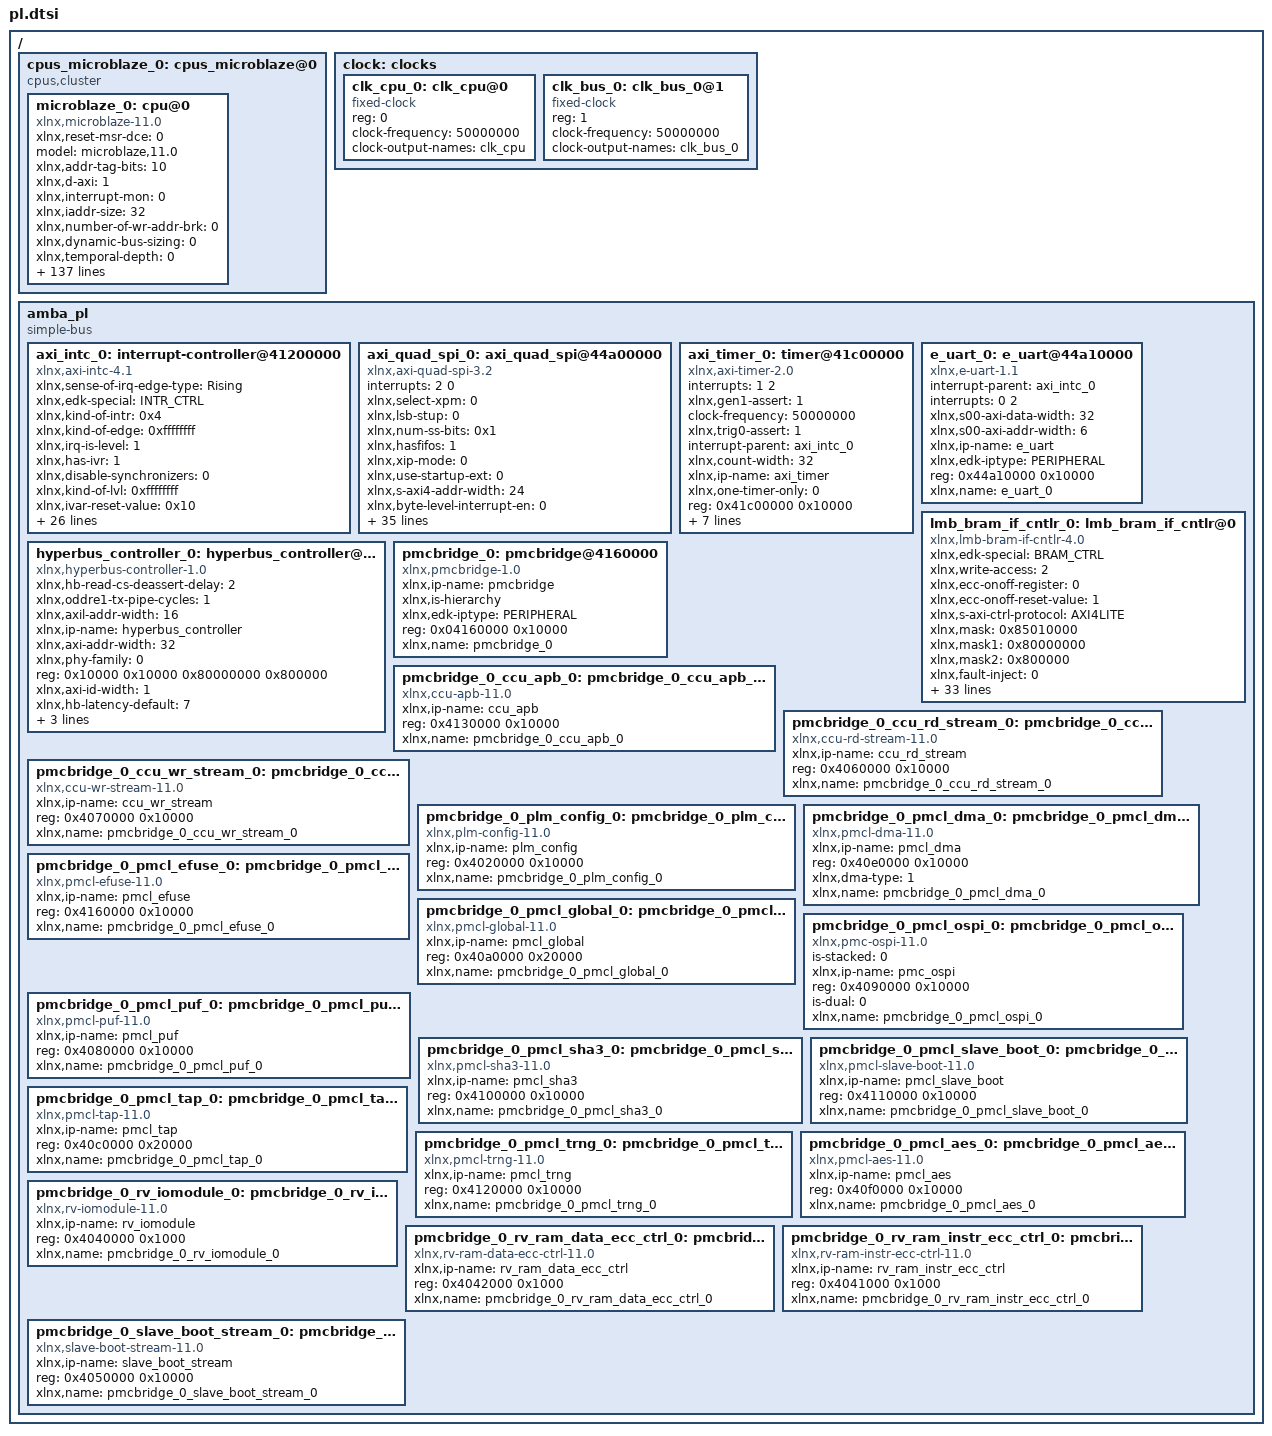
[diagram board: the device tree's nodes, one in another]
/ {
	cpus_microblaze_0: cpus_microblaze@0 {
		#cpu-mask-cells = <1>;
		compatible = "cpus,cluster";
		#address-cells = <1>;
		#size-cells = <0>;
		microblaze_0: cpu@0 {
			xlnx,reset-msr-dce = <0>;
			model = "microblaze,11.0";
			xlnx,addr-tag-bits = <10>;
			xlnx,d-axi = <1>;
			xlnx,interrupt-mon = <0>;
			xlnx,iaddr-size = <32>;
			xlnx,number-of-wr-addr-brk = <0>;
			xlnx,dynamic-bus-sizing = <0>;
			xlnx,temporal-depth = <0>;
			xlnx,use-interrupt = <1>;
			xlnx,optimization = <0>;
			xlnx,ip-axi-mon = <0>;
			xlnx,ip-name = "microblaze";
			d-cache-highaddr = <0x807fffff>;
			xlnx,dcache-force-tag-lutram = <0>;
			xlnx,pc-width = <32>;
			xlnx,interrupt-is-edge = <0>;
			reg = <0x0>;
			xlnx,async-interrupt = <1>;
			xlnx,use-mmu = <0>;
			xlnx,reset-msr-ee = <0>;
			xlnx,icache-victims = <0>;
			xlnx,use-reorder-instr = <1>;
			xlnx,d-lmb-mon = <0>;
			xlnx,d-lmb-protocol = <0>;
			xlnx,ill-opcode-exception = <1>;
			xlnx,dcache-always-used = <1>;
			xlnx,use-div = <1>;
			xlnx,dc-axi-mon = <0>;
			xlnx,debug-trace-async-reset = <0>;
			xlnx,trace = <0>;
			xlnx,part = "xcsu35p-sbvb625-2-e";
			i-cache-baseaddr = <0x80000000>;
			xlnx,use-config-reset = <0>;
			xlnx,pvr = <0>;
			xlnx,i-lmb-mon = <0>;
			xlnx,dcache-byte-size = <8192>;
			xlnx,fault-tolerant = <0>;
			xlnx,family = "spartanuplus";
			compatible = "xlnx,microblaze-11.0" , "xlnx,microblaze";
			xlnx,data-size = <32>;
			xlnx,mmu-zones = <16>;
			xlnx,debug-trace-size = <8192>;
			xlnx,mmu-privileged-instr = <0>;
			xlnx,enable-discrete-ports = <0>;
			d-cache-line-size = <32>;
			xlnx,d-lmb = <1>;
			xlnx,sco = <0>;
			xlnx,reset-msr-eip = <0>;
			xlnx,debug-interface = <0>;
			clock-frequency = <50000000>;
			xlnx,use-ext-brk = <0>;
			xlnx,daddr-size = <32>;
			xlnx,debug-enabled = <1>;
			xlnx,reset-msr-ice = <0>;
			xlnx,num-sync-ff-dbg-trace-clk = <2>;
			xlnx,i-lmb-protocol = <0>;
			xlnx,endianness = <1>;
			xlnx,fsl-exception = <0>;
			i-cache-line-size = <32>;
			xlnx,use-extended-fsl-instr = <0>;
			xlnx,reset-msr = <0x0>;
			xlnx,dp-axi-mon = <0>;
			device_type = "cpu";
			xlnx,branch-target-cache-size = <0>;
			xlnx,dcache-use-writeback = <0>;
			xlnx,div-zero-exception = <1>;
			xlnx,mmu-tlb-access = <3>;
			bus-handle = <&amba_pl>;
			xlnx,cache-byte-size = <8192>;
			xlnx,pvr-user2 = <0x0>;
			xlnx,opcode-0x0-illegal = <1>;
			xlnx,icache-line-len = <8>;
			xlnx,ecc-use-ce-exception = <0>;
			xlnx,base-vectors = <0x0>;
			xlnx,d-lmb-has-prot = <0>;
			xlnx,edk-special = "microblaze";
			xlnx,use-dcache = <1>;
			xlnx,use-barrel = <1>;
			xlnx,reset-msr-bip = <0>;
			xlnx,allow-dcache-wr = <1>;
			xlnx,debug-external-trace = <0>;
			xlnx,addr-size = <32>;
			xlnx,piaddr-size = <32>;
			i-cache-highaddr = <0x807fffff>;
			xlnx,num-sync-ff-clk-debug = <2>;
			xlnx,debug-event-counters = <5>;
			xlnx,fpu-exception = <1>;
			xlnx,allow-icache-wr = <1>;
			xlnx,g-use-exceptions = <1>;
			xlnx,i-axi = <0>;
			xlnx,g-template-list = <0>;
			xlnx,icache-streams = <0>;
			xlnx,dcache-line-len = <8>;
			xlnx,num-sync-ff-clk = <2>;
			xlnx,edk-iptype = "PROCESSOR";
			xlnx,use-stack-protection = <1>;
			xlnx,use-hw-mul = <1>;
			xlnx,num-sync-ff-dbg-clk = <1>;
			xlnx,interconnect = <2>;
			xlnx,i-lmb-has-prot = <0>;
			xlnx,debug-latency-counters = <1>;
			i-cache-size = <8192>;
			xlnx,exceptions-in-delay-slots = <1>;
			xlnx,use-fpu = <1>;
			xlnx,reset-msr-ie = <0>;
			xlnx,edge-is-positive = <1>;
			xlnx,use-pcmp-instr = <1>;
			xlnx,use-icache = <1>;
			d-cache-size = <8192>;
			xlnx,memory-ip-list = "lmb_bram_if_cntlr_0_memory" , "lmb_bram_if_cntlr_0_memory";
			xlnx,async-wakeup = <3>;
			xlnx,use-non-secure = <0>;
			xlnx,dcache-addr-tag = <10>;
			xlnx,number-of-rd-addr-brk = <0>;
			d-cache-baseaddr = <0x80000000>;
			xlnx,area-optimized = <1>;
			xlnx,avoid-primitives = <0>;
			xlnx,lockstep-slave = <0>;
			xlnx,use-ext-nm-brk = <0>;
			xlnx,instr-size = <32>;
			interrupt-handle = <&axi_intc_0>;
			xlnx,icache-always-used = <1>;
			xlnx,i-lmb = <1>;
			xlnx,mmu-dtlb-size = <4>;
			xlnx,lockstep-select = <0>;
			xlnx,lmb-data-size = <32>;
			xlnx,ic-axi-mon = <0>;
			xlnx,enable-conversion = <1>;
			xlnx,num-sync-ff-clk-irq = <1>;
			xlnx,fsl-links = <0>;
			timebase-frequency = <50000000>;
			xlnx,icache-force-tag-lutram = <0>;
			xlnx,dcache-data-width = <0>;
			xlnx,dcache-victims = <0>;
			xlnx,use-branch-target-cache = <0>;
			xlnx,debug-profile-size = <0>;
			xlnx,unaligned-exceptions = <1>;
			xlnx,lockstep-master = <0>;
			xlnx,freq = <50000000>;
			xlnx,number-of-pc-brk = <1>;
			xlnx,mmu-itlb-size = <2>;
			xlnx,imprecise-exceptions = <0>;
			xlnx,use-msr-instr = <1>;
			xlnx,icache-data-width = <0>;
			xlnx,debug-counter-width = <32>;
		};
	};
	clock: clocks {
		#address-cells = <1>;
		#size-cells = <0>;
		clk_cpu_0: clk_cpu@0 {
			compatible = "fixed-clock";
			reg = <0>;
			clock-frequency = <50000000>;
			clock-output-names = "clk_cpu";
			#clock-cells = <0>;
		};
		clk_bus_0: clk_bus_0@1 {
			compatible = "fixed-clock";
			reg = <1>;
			clock-frequency = <50000000>;
			clock-output-names = "clk_bus_0";
			#clock-cells = <0>;
		};
	};
	amba_pl: amba_pl {
		ranges;
		compatible = "simple-bus";
		#address-cells = <1>;
		#size-cells = <1>;
		axi_intc_0: interrupt-controller@41200000 {
			#interrupt-cells = <2>;
			xlnx,sense-of-irq-edge-type = "Rising";
			xlnx,edk-special = "INTR_CTRL";
			xlnx,kind-of-intr = <0x4>;
			xlnx,kind-of-edge = <0xffffffff>;
			xlnx,irq-is-level = <1>;
			xlnx,has-ivr = <1>;
			compatible = "xlnx,axi-intc-4.1" , "xlnx,xps-intc-1.00.a";
			xlnx,disable-synchronizers = <0>;
			xlnx,kind-of-lvl = <0xffffffff>;
			xlnx,ivar-reset-value = <0x10>;
			xlnx,irq-active = <0x1>;
			xlnx,en-cascade-mode = <0>;
			xlnx,ip-name = "axi_intc";
			xlnx,has-ilr = <0>;
			reg = <0x41200000 0x10000>;
			xlnx,addr-width = <0x20>;
			xlnx,s-axi-aclk-freq-mhz = <50>;
			xlnx,num-sw-intr = <0>;
			xlnx,irq-connection = <0>;
			xlnx,num-intr-inputs = <0x3>;
			xlnx,has-sie = <1>;
			xlnx,enable-async = <0>;
			xlnx,has-cie = <1>;
			xlnx,num-sync-ff = <2>;
			xlnx,edk-iptype = "PERIPHERAL";
			xlnx,mb-clk-not-connected = <1>;
			xlnx,has-ipr = <1>;
			xlnx,sense-of-irq-level-type = "Active_High";
			xlnx,cascade-master = <0>;
			xlnx,processor-clk-freq-mhz = <100>;
			status = "okay";
			xlnx,is-fast = <0x0>;
			xlnx,has-fast = <0>;
			xlnx,ivar-rst-val = <0x10>;
			interrupt-controller;
			xlnx,async-intr = <0xfffffffc>;
			xlnx,name = "axi_intc_0";
		};
		axi_quad_spi_0: axi_quad_spi@44a00000 {
			interrupts = < 2 0 >;
			xlnx,select-xpm = <0>;
			compatible = "xlnx,axi-quad-spi-3.2" , "xlnx,xps-spi-2.00.a";
			xlnx,lsb-stup = <0>;
			xlnx,num-ss-bits = <0x1>;
			xlnx,hasfifos = <1>;
			xlnx,xip-mode = <0>;
			xlnx,use-startup-ext = <0>;
			xlnx,s-axi4-addr-width = <24>;
			xlnx,byte-level-interrupt-en = <0>;
			num-cs = <0x1>;
			xlnx,xip-perf-mode = <1>;
			xlnx,sck-ratio = <2>;
			xlnx,s-axi4-id-width = <4>;
			fifo-size = <256>;
			interrupt-parent = <&axi_intc_0>;
			xlnx,multiples16 = <1>;
			xlnx,master-mode = <1>;
			xlnx,shared-startup = <0>;
			xlnx,ip-name = "axi_quad_spi";
			xlnx,qspi-board-interface = "Custom";
			reg = <0x44a00000 0x10000>;
			xlnx,dual-quad-mode = <0>;
			xlnx,new-seq-en = <1>;
			bits-per-word = <8>;
			xlnx,num-transfer-bits = <8>;
			xlnx,spi-memory = <2>;
			xlnx,s-axi4-data-width = <32>;
			xlnx,startup-block;
			xlnx,edk-iptype = "PERIPHERAL";
			xlnx,slaveonly = <0>;
			xlnx,use-startup-int = <1>;
			xlnx,use-startup = <1>;
			xlnx,type-of-axi4-interface = <0>;
			xlnx,async-clk = <0>;
			xlnx,spi-mode = <2>;
			xlnx,sck-ratio1 = <1>;
			status = "okay";
			xlnx,fifo-depth = <256>;
			xlnx,uc-family = <1>;
			xlnx,spi-mem-addr-bits = <24>;
			xlnx,axi-interface = <0>;
			interrupt-names = "ip2intc_irpt";
			xlnx,Axi4-address = <0>;
			xlnx,fifo-included = <1>;
			xlnx,sub-family = "spartanuplus";
			xlnx,name = "axi_quad_spi_0";
		};
		axi_timer_0: timer@41c00000 {
			interrupts = < 1 2 >;
			compatible = "xlnx,axi-timer-2.0" , "xlnx,xps-timer-1.00.a";
			xlnx,gen1-assert = <1>;
			clock-frequency = <50000000>;
			xlnx,trig0-assert = <1>;
			interrupt-parent = <&axi_intc_0>;
			xlnx,count-width = <32>;
			xlnx,ip-name = "axi_timer";
			xlnx,one-timer-only = <0>;
			reg = <0x41c00000 0x10000>;
			clocks = <&clk_bus_0>;
			xlnx,gen0-assert = <1>;
			xlnx,mode-64bit = <0>;
			xlnx,edk-iptype = "PERIPHERAL";
			status = "okay";
			xlnx,trig1-assert = <1>;
			xlnx,enable-timer2 = <1>;
			interrupt-names = "interrupt";
			xlnx,name = "axi_timer_0";
		};
		e_uart_0: e_uart@44a10000 {
			interrupt-parent = <&axi_intc_0>;
			interrupts = < 0 2 >;
			xlnx,s00-axi-data-width = <32>;
			compatible = "xlnx,e-uart-1.1";
			status = "okay";
			xlnx,s00-axi-addr-width = <6>;
			xlnx,ip-name = "e_uart";
			interrupt-names = "intr";
			xlnx,edk-iptype = "PERIPHERAL";
			reg = <0x44a10000 0x10000>;
			xlnx,name = "e_uart_0";
		};
		hyperbus_controller_0: hyperbus_controller@10000 {
			compatible = "xlnx,hyperbus-controller-1.0";
			xlnx,hb-read-cs-deassert-delay = <2>;
			xlnx,oddre1-tx-pipe-cycles = <1>;
			xlnx,axil-addr-width = <16>;
			xlnx,ip-name = "hyperbus_controller";
			xlnx,axi-addr-width = <32>;
			xlnx,phy-family = <0>;
			reg = <0x10000 0x10000 0x80000000 0x800000>;
			xlnx,axi-id-width = <1>;
			xlnx,hb-latency-default = <7>;
			xlnx,edk-iptype = "PERIPHERAL";
			status = "okay";
			xlnx,axi-data-width = <32>;
			xlnx,name = "hyperbus_controller_0";
		};
		lmb_bram_if_cntlr_0: lmb_bram_if_cntlr@0 {
			xlnx,edk-special = "BRAM_CTRL";
			xlnx,write-access = <2>;
			compatible = "xlnx,lmb-bram-if-cntlr-4.0" , "xlnx,axi-bram-ctrl";
			xlnx,ecc-onoff-register = <0>;
			xlnx,ecc-onoff-reset-value = <1>;
			xlnx,s-axi-ctrl-protocol = "AXI4LITE";
			xlnx,mask = <0x85010000>;
			xlnx,mask1 = <0x80000000>;
			xlnx,mask2 = <0x800000>;
			xlnx,fault-inject = <0>;
			xlnx,mask3 = <0x800000>;
			xlnx,ip-name = "lmb_bram_if_cntlr";
			xlnx,arbitration = <0>;
			xlnx,num-lmb = <2>;
			xlnx,mask4 = <0x800000>;
			reg = <0x0000 0x8000>;
			xlnx,s-axi-ctrl-addr-width = <32>;
			xlnx,mask5 = <0x800000>;
			xlnx,ecc-status-registers = <0>;
			xlnx,prot-cfg = <0xff>;
			xlnx,mask6 = <0x800000>;
			xlnx,lmb-protocol = <0>;
			xlnx,ce-counter-width = <0>;
			xlnx,prot-cfg1 = <0xff>;
			xlnx,mask7 = <0x800000>;
			xlnx,ecc = <0>;
			xlnx,edk-iptype = "PERIPHERAL";
			xlnx,prot-cfg2 = <0xff>;
			xlnx,lmb-dwidth = <32>;
			xlnx,interconnect = <0>;
			xlnx,ce-failing-registers = <0>;
			xlnx,prot-cfg3 = <0xff>;
			xlnx,ue-failing-registers = <0>;
			xlnx,prot-cfg4 = <0xff>;
			xlnx,lmb-has-prot = <0>;
			status = "okay";
			xlnx,data-width = <32>;
			xlnx,prot-cfg5 = <0xff>;
			xlnx,s-axi-ctrl-data-width = <32>;
			xlnx,prot-cfg6 = <0xff>;
			xlnx,bram-awidth = <32>;
			xlnx,prot-cfg7 = <0xff>;
			xlnx,lmb-awidth = <32>;
			xlnx,name = "lmb_bram_if_cntlr_0";
		};
		pmcbridge_0: pmcbridge@4160000 {
			compatible = "xlnx,pmcbridge-1.0";
			status = "okay";
			xlnx,ip-name = "pmcbridge";
			xlnx,is-hierarchy;
			xlnx,edk-iptype = "PERIPHERAL";
			reg = <0x04160000 0x10000>;
			xlnx,name = "pmcbridge_0";
		};
		pmcbridge_0_ccu_apb_0: pmcbridge_0_ccu_apb_0@4130000 {
			compatible = "xlnx,ccu-apb-11.0";
			status = "okay";
			xlnx,ip-name = "ccu_apb";
			reg = <0x4130000 0x10000>;
			xlnx,name = "pmcbridge_0_ccu_apb_0";
		};
		pmcbridge_0_ccu_rd_stream_0: pmcbridge_0_ccu_rd_stream_0@4060000 {
			compatible = "xlnx,ccu-rd-stream-11.0";
			status = "okay";
			xlnx,ip-name = "ccu_rd_stream";
			reg = <0x4060000 0x10000>;
			xlnx,name = "pmcbridge_0_ccu_rd_stream_0";
		};
		pmcbridge_0_ccu_wr_stream_0: pmcbridge_0_ccu_wr_stream_0@4070000 {
			compatible = "xlnx,ccu-wr-stream-11.0";
			status = "okay";
			xlnx,ip-name = "ccu_wr_stream";
			reg = <0x4070000 0x10000>;
			xlnx,name = "pmcbridge_0_ccu_wr_stream_0";
		};
		pmcbridge_0_plm_config_0: pmcbridge_0_plm_config_0@4020000 {
			compatible = "xlnx,plm-config-11.0";
			status = "okay";
			xlnx,ip-name = "plm_config";
			reg = <0x4020000 0x10000>;
			xlnx,name = "pmcbridge_0_plm_config_0";
		};
		pmcbridge_0_pmcl_dma_0: pmcbridge_0_pmcl_dma_0@40e0000 {
			compatible = "xlnx,pmcl-dma-11.0" , "xlnx,pmc-dma";
			status = "okay";
			xlnx,ip-name = "pmcl_dma";
			reg = <0x40e0000 0x10000>;
			xlnx,dma-type = <1>;
			xlnx,name = "pmcbridge_0_pmcl_dma_0";
		};
		pmcbridge_0_pmcl_efuse_0: pmcbridge_0_pmcl_efuse_0@4160000 {
			compatible = "xlnx,pmcl-efuse-11.0";
			status = "okay";
			xlnx,ip-name = "pmcl_efuse";
			reg = <0x4160000 0x10000>;
			xlnx,name = "pmcbridge_0_pmcl_efuse_0";
		};
		pmcbridge_0_pmcl_global_0: pmcbridge_0_pmcl_global_0@40a0000 {
			compatible = "xlnx,pmcl-global-11.0";
			status = "okay";
			xlnx,ip-name = "pmcl_global";
			reg = <0x40a0000 0x20000>;
			xlnx,name = "pmcbridge_0_pmcl_global_0";
		};
		pmcbridge_0_pmcl_ospi_0: pmcbridge_0_pmcl_ospi_0@4090000 {
			is-stacked = <0>;
			compatible = "xlnx,pmc-ospi-11.0" , "xlnx,pmc-ospi";
			status = "okay";
			xlnx,ip-name = "pmc_ospi";
			reg = <0x4090000 0x10000>;
			is-dual = <0>;
			xlnx,name = "pmcbridge_0_pmcl_ospi_0";
		};
		pmcbridge_0_pmcl_puf_0: pmcbridge_0_pmcl_puf_0@4080000 {
			compatible = "xlnx,pmcl-puf-11.0";
			status = "okay";
			xlnx,ip-name = "pmcl_puf";
			reg = <0x4080000 0x10000>;
			xlnx,name = "pmcbridge_0_pmcl_puf_0";
		};
		pmcbridge_0_pmcl_sha3_0: pmcbridge_0_pmcl_sha3_0@4100000 {
			compatible = "xlnx,pmcl-sha3-11.0";
			status = "okay";
			xlnx,ip-name = "pmcl_sha3";
			reg = <0x4100000 0x10000>;
			xlnx,name = "pmcbridge_0_pmcl_sha3_0";
		};
		pmcbridge_0_pmcl_slave_boot_0: pmcbridge_0_pmcl_slave_boot_0@4110000 {
			compatible = "xlnx,pmcl-slave-boot-11.0";
			status = "okay";
			xlnx,ip-name = "pmcl_slave_boot";
			reg = <0x4110000 0x10000>;
			xlnx,name = "pmcbridge_0_pmcl_slave_boot_0";
		};
		pmcbridge_0_pmcl_tap_0: pmcbridge_0_pmcl_tap_0@40c0000 {
			compatible = "xlnx,pmcl-tap-11.0";
			status = "okay";
			xlnx,ip-name = "pmcl_tap";
			reg = <0x40c0000 0x20000>;
			xlnx,name = "pmcbridge_0_pmcl_tap_0";
		};
		pmcbridge_0_pmcl_trng_0: pmcbridge_0_pmcl_trng_0@4120000 {
			compatible = "xlnx,pmcl-trng-11.0";
			status = "okay";
			xlnx,ip-name = "pmcl_trng";
			reg = <0x4120000 0x10000>;
			xlnx,name = "pmcbridge_0_pmcl_trng_0";
		};
		pmcbridge_0_pmcl_aes_0: pmcbridge_0_pmcl_aes_0@40f0000 {
			compatible = "xlnx,pmcl-aes-11.0";
			status = "okay";
			xlnx,ip-name = "pmcl_aes";
			reg = <0x40f0000 0x10000>;
			xlnx,name = "pmcbridge_0_pmcl_aes_0";
		};
		pmcbridge_0_rv_iomodule_0: pmcbridge_0_rv_iomodule_0@4040000 {
			compatible = "xlnx,rv-iomodule-11.0";
			status = "okay";
			xlnx,ip-name = "rv_iomodule";
			reg = <0x4040000 0x1000>;
			xlnx,name = "pmcbridge_0_rv_iomodule_0";
		};
		pmcbridge_0_rv_ram_data_ecc_ctrl_0: pmcbridge_0_rv_ram_data_ecc_ctrl_0@4042000 {
			compatible = "xlnx,rv-ram-data-ecc-ctrl-11.0";
			status = "okay";
			xlnx,ip-name = "rv_ram_data_ecc_ctrl";
			reg = <0x4042000 0x1000>;
			xlnx,name = "pmcbridge_0_rv_ram_data_ecc_ctrl_0";
		};
		pmcbridge_0_rv_ram_instr_ecc_ctrl_0: pmcbridge_0_rv_ram_instr_ecc_ctrl_0@4041000 {
			compatible = "xlnx,rv-ram-instr-ecc-ctrl-11.0";
			status = "okay";
			xlnx,ip-name = "rv_ram_instr_ecc_ctrl";
			reg = <0x4041000 0x1000>;
			xlnx,name = "pmcbridge_0_rv_ram_instr_ecc_ctrl_0";
		};
		pmcbridge_0_slave_boot_stream_0: pmcbridge_0_slave_boot_stream_0@4050000 {
			compatible = "xlnx,slave-boot-stream-11.0";
			status = "okay";
			xlnx,ip-name = "slave_boot_stream";
			reg = <0x4050000 0x10000>;
			xlnx,name = "pmcbridge_0_slave_boot_stream_0";
		};
	};
};
